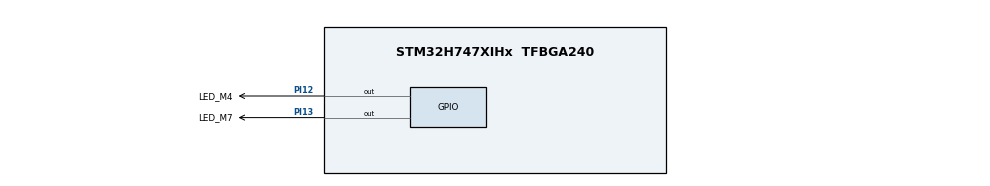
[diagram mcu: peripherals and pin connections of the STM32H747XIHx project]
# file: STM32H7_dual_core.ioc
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CORTEX_M7.CPU_DCache=Enabled
CORTEX_M7.CPU_ICache=Enabled
CortexM4.IPs=BDMA,CORTEX_M4\:I,DEBUG,DMA,FATFS_M4\:I,FREERTOS_M4\:I,IWDG2\:I,MDMA,NVIC2\:I,OPENAMP_M4\:I,PDM2PCM_M4\:I,PWR,RCC,RESMGR_UTILITY,SYS_M4\:I,USB_DEVICE_M4\:I,USB_HOST_M4\:I,VREFBUF,WWDG2\:I,TIM3\:I
CortexM4.Pins=PI12
CortexM7.IPs=BDMA\:I,CORTEX_M7\:I,DEBUG\:I,DMA\:I,FATFS_M7\:I,FREERTOS_M7\:I,IWDG1\:I,MDMA\:I,NVIC1\:I,OPENAMP_M7\:I,PDM2PCM_M7\:I,PWR\:I,RCC\:I,RESMGR_UTILITY\:I,SYS\:I,USB_DEVICE_M7\:I,USB_HOST_M7\:I,VREFBUF\:I,WWDG1\:I,TIM2\:I
CortexM7.Pins=PI13
FREERTOS_M4.Tasks01=defaultTask,24,256,StartDefaultTask,Default,NULL,Dynamic,NULL,NULL
FREERTOS_M4.configENABLE_FPU=1
FREERTOS_M4.configMINIMAL_STACK_SIZE=256
FREERTOS_M4.configUSE_NEWLIB_REENTRANT=1
FREERTOS_M7.Tasks01=defaultTask,24,128,StartDefaultTask,Default,NULL,Dynamic,NULL,NULL
FREERTOS_M7.configENABLE_FPU=1
FREERTOS_M7.configUSE_NEWLIB_REENTRANT=1
Mcu.Family=STM32H7
Mcu.Name=STM32H747XIHx
Mcu.Package=TFBGA240
NVIC1.PriorityGroup=NVIC_PRIORITYGROUP_4
NVIC1.TIM2_IRQn=true\:15\:0\:false\:false\:true\:false\:false\:true
NVIC1.TimeBase=TIM2_IRQn
NVIC1.TimeBaseIP=TIM2
NVIC2.PriorityGroup=NVIC_PRIORITYGROUP_4
NVIC2.TIM3_IRQn=true\:15\:0\:false\:false\:true\:false\:false\:true
NVIC2.TimeBase=TIM3_IRQn
NVIC2.TimeBaseIP=TIM3
PH0-OSC_IN\ (PH0).Mode=HSE-External-Oscillator
PH0-OSC_IN\ (PH0).PinAttribute=CortexM7
PH0-OSC_IN\ (PH0).Signal=RCC_OSC_IN
PH1-OSC_OUT\ (PH1).Mode=HSE-External-Oscillator
PH1-OSC_OUT\ (PH1).PinAttribute=CortexM7
PH1-OSC_OUT\ (PH1).Signal=RCC_OSC_OUT
PI12.GPIO_Label=LED_M4
PI12.PinAttribute=CortexM4
PI12.Signal=GPIO_Output
PI13.GPIO_Label=LED_M7
PI13.PinAttribute=CortexM7
PI13.Signal=GPIO_Output
ProjectManager.HeapSize=M4-0x200,M7-0x200
ProjectManager.StackSize=M4-0x400,M7-0x400
ProjectManager.TargetToolchain=STM32CubeIDE
RCC.ADCFreq_Value=50390625
RCC.APB1Freq_Value=120000000
RCC.APB2Freq_Value=120000000
RCC.APB3Freq_Value=120000000
RCC.APB4Freq_Value=120000000
RCC.CortexFreq_Value=480000000
RCC.D1PPRE=RCC_APB3_DIV2
RCC.D2PPRE1=RCC_APB1_DIV2
RCC.D2PPRE2=RCC_APB2_DIV2
RCC.D3PPRE=RCC_APB4_DIV2
RCC.DIVM1=5
RCC.DIVN1=192
RCC.HCLKFreq_Value=240000000
RCC.HPRE=RCC_HCLK_DIV2
RCC.PLLFRACN=0
RCC.PLLSourceVirtual=RCC_PLLSOURCE_HSE
RCC.SYSCLKFreq_VALUE=480000000
RCC.SYSCLKSource=RCC_SYSCLKSOURCE_PLLCLK
RCC.USBFreq_Value=480000000
SYS.userName=SYS_M7
VP_FREERTOS_M4_VS_CMSIS_V2.Mode=CMSIS_V2
VP_FREERTOS_M7_VS_CMSIS_V2.Mode=CMSIS_V2
VP_SYS_M4_VS_tim3.Mode=TIM3
VP_SYS_VS_tim2.Mode=TIM2
board=custom

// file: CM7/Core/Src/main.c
/* USER CODE BEGIN Header */
/**
  ******************************************************************************
  * @file           : main.c
  * @brief          : Main program body
  ******************************************************************************
  * @attention
  *
  * <h2><center>&copy; Copyright (c) 2021 STMicroelectronics.
  * All rights reserved.</center></h2>
  *
  * This software component is licensed by ST under BSD 3-Clause license,
  * the "License"; You may not use this file except in compliance with the
  * License. You may obtain a copy of the License at:
  *                        opensource.org/licenses/BSD-3-Clause
  *
  ******************************************************************************
  */
/* USER CODE END Header */
#include "main.h"
#include "cmsis_os.h"

/* USER CODE BEGIN Includes */
#include "cm_ipc.h"
#include <stdio.h>
#include "stm32h747i_discovery.h"
#include "hal_stm_lvgl/tft/tft.h"
#include "hal_stm_lvgl/touchpad/touchpad.h"
#include "lvgl/lvgl.h"
#include "GUI/gui.h"
/* USER CODE END Includes */

/* USER CODE BEGIN PTD */
volatile int lv_started = 0;
void GUITask(void *argument);
osThreadId_t guiTaskHandle;
const osThreadAttr_t guiTask_attributes = {
  .name = "GUITask",
  .stack_size = 1024 * 3,
  .priority = (osPriority_t) osPriorityLow,
};

void MPU_Config( void )
{
  MPU_Region_InitTypeDef MPU_InitStruct;

  /* Disable the MPU */
  HAL_MPU_Disable();

  /* Setup AXI SRAM in Write-through */
  MPU_InitStruct.Enable           = MPU_REGION_ENABLE;
  MPU_InitStruct.BaseAddress      = D1_AXISRAM_BASE;
  MPU_InitStruct.Size             = MPU_REGION_SIZE_512KB;
  MPU_InitStruct.AccessPermission = MPU_REGION_FULL_ACCESS;
  MPU_InitStruct.IsBufferable     = MPU_ACCESS_NOT_BUFFERABLE;
  MPU_InitStruct.IsCacheable      = MPU_ACCESS_CACHEABLE;
  MPU_InitStruct.IsShareable      = MPU_ACCESS_NOT_SHAREABLE;
  MPU_InitStruct.Number           = MPU_REGION_NUMBER0;
  MPU_InitStruct.TypeExtField     = MPU_TEX_LEVEL0;
  MPU_InitStruct.SubRegionDisable = 0x00;
  MPU_InitStruct.DisableExec      = MPU_INSTRUCTION_ACCESS_DISABLE;
  HAL_MPU_ConfigRegion(&MPU_InitStruct);

  /* Disable access to D2 SRAM1 */
  MPU_InitStruct.Enable           = MPU_REGION_ENABLE;
  MPU_InitStruct.BaseAddress      = D2_AXISRAM_BASE;
  MPU_InitStruct.Size             = MPU_REGION_SIZE_256KB;
  MPU_InitStruct.AccessPermission = MPU_REGION_NO_ACCESS;
  MPU_InitStruct.IsBufferable     = MPU_ACCESS_NOT_BUFFERABLE;
  MPU_InitStruct.IsCacheable      = MPU_ACCESS_NOT_CACHEABLE;
  MPU_InitStruct.IsShareable      = MPU_ACCESS_NOT_SHAREABLE;
  MPU_InitStruct.Number           = MPU_REGION_NUMBER1;
  MPU_InitStruct.TypeExtField     = MPU_TEX_LEVEL0;
  MPU_InitStruct.SubRegionDisable = 0x00;
  MPU_InitStruct.DisableExec      = MPU_INSTRUCTION_ACCESS_DISABLE;
  HAL_MPU_ConfigRegion(&MPU_InitStruct);

  /* Setup D2 SRAM2 as device memory */
  MPU_InitStruct.Enable           = MPU_REGION_ENABLE;
  MPU_InitStruct.BaseAddress      = (D2_AXISRAM_BASE + 0x40000);
  MPU_InitStruct.Size             = MPU_REGION_SIZE_32KB;
  MPU_InitStruct.AccessPermission = MPU_REGION_FULL_ACCESS;
  MPU_InitStruct.IsBufferable     = MPU_ACCESS_BUFFERABLE;
  MPU_InitStruct.IsCacheable      = MPU_ACCESS_NOT_CACHEABLE;
  MPU_InitStruct.IsShareable      = MPU_ACCESS_NOT_SHAREABLE;
  MPU_InitStruct.Number           = MPU_REGION_NUMBER2;
  MPU_InitStruct.TypeExtField     = MPU_TEX_LEVEL0;
  MPU_InitStruct.SubRegionDisable = 0x00;
  MPU_InitStruct.DisableExec      = MPU_INSTRUCTION_ACCESS_DISABLE;
  HAL_MPU_ConfigRegion(&MPU_InitStruct);

	// Enable D-cache on SDRAM (Write-through)
  MPU_InitStruct.Enable           = MPU_REGION_ENABLE;
  MPU_InitStruct.BaseAddress      = 0xD0000000U;
  MPU_InitStruct.Size             = MPU_REGION_SIZE_32MB;
  MPU_InitStruct.AccessPermission = MPU_REGION_FULL_ACCESS;
  MPU_InitStruct.IsBufferable     = MPU_ACCESS_NOT_BUFFERABLE;
  MPU_InitStruct.IsCacheable      = MPU_ACCESS_CACHEABLE;
  MPU_InitStruct.IsShareable      = MPU_ACCESS_NOT_SHAREABLE;
  MPU_InitStruct.Number           = MPU_REGION_NUMBER3;
  MPU_InitStruct.TypeExtField     = MPU_TEX_LEVEL0;
  MPU_InitStruct.SubRegionDisable = 0x00;
  MPU_InitStruct.DisableExec      = MPU_INSTRUCTION_ACCESS_DISABLE;
  HAL_MPU_ConfigRegion(&MPU_InitStruct);

  /* Disable access to D2 SRAM3 */
  /*
  MPU_InitStruct.Enable           = MPU_REGION_ENABLE;
  MPU_InitStruct.BaseAddress      = D3_SRAM_BASE;
  MPU_InitStruct.Size             = MPU_REGION_SIZE_64KB;
  MPU_InitStruct.AccessPermission = MPU_REGION_NO_ACCESS;
  MPU_InitStruct.IsBufferable     = MPU_ACCESS_BUFFERABLE;
  MPU_InitStruct.IsCacheable      = MPU_ACCESS_NOT_CACHEABLE;
  MPU_InitStruct.IsShareable      = MPU_ACCESS_NOT_SHAREABLE;
  MPU_InitStruct.Number           = MPU_REGION_NUMBER7;
  MPU_InitStruct.TypeExtField     = MPU_TEX_LEVEL0;
  MPU_InitStruct.SubRegionDisable = 0x00;
  MPU_InitStruct.DisableExec      = MPU_INSTRUCTION_ACCESS_DISABLE;
  HAL_MPU_ConfigRegion(&MPU_InitStruct);
  */

  HAL_MPU_Enable(MPU_PRIVILEGED_DEFAULT);
}
/* USER CODE END PTD */

/* USER CODE BEGIN PD */

#ifndef HSEM_ID_0
#define HSEM_ID_0 (0U) /* HW semaphore 0*/
#endif
/* USER CODE END PD */

/* Definitions for defaultTask */
osThreadId_t defaultTaskHandle;
const osThreadAttr_t defaultTask_attributes = {
  .name = "defaultTask",
  .stack_size = 128 * 4,
  .priority = (osPriority_t) osPriorityNormal,
};
/* USER CODE BEGIN PV */
#if configAPPLICATION_ALLOCATED_HEAP == 1
#if defined ( __ICCARM__ )
#pragma location="heap_mem"
#else
__attribute__((section("heap_mem")))
#endif
uint8_t ucHeap[ configTOTAL_HEAP_SIZE ];
#endif /* configAPPLICATION_ALLOCATED_HEAP */

uint8_t                 DualCoreEnabled = 0;

/* USER CODE END PV */

void SystemClock_Config(void);
static void MX_GPIO_Init(void);
void StartDefaultTask(void *argument);

int main(void)
{
  /* USER CODE BEGIN 1 */
  /* Wait until CPU2 boots and enters in stop mode or timeout*/
  int32_t timeout = 0xFFFF;
  while((__HAL_RCC_GET_FLAG(RCC_FLAG_D2CKRDY) != RESET) && (timeout-- > 0));
  if ( timeout == 0 )
  {
	DualCoreEnabled = 0;
  }
  else
  {
	DualCoreEnabled = 1;
  }

  MPU_Config();
  /* USER CODE END 1 */
/* USER CODE BEGIN Boot_Mode_Sequence_0 */
  //int32_t timeout;
/* USER CODE END Boot_Mode_Sequence_0 */

  /* Enable I-Cache---------------------------------------------------------*/
  SCB_EnableICache();

  /* Enable D-Cache---------------------------------------------------------*/
  SCB_EnableDCache();

/* USER CODE BEGIN Boot_Mode_Sequence_1 */
  /* Wait until CPU2 boots and enters in stop mode or timeout*/
  //timeout = 0xFFFF;
  /*
  while((__HAL_RCC_GET_FLAG(RCC_FLAG_D2CKRDY) != RESET) && (timeout-- > 0));
  if ( timeout < 0 )
  {
  Error_Handler();
  }
  */
/* USER CODE END Boot_Mode_Sequence_1 */
  /* MCU Configuration--------------------------------------------------------*/

  /* Reset of all peripherals, Initializes the Flash interface and the Systick. */
  HAL_Init();

  /* USER CODE BEGIN Init */
  /* WA : Allow Debugger to connect under reset */
  //HAL_Delay(1000);
  /* USER CODE END Init */

  /* Configure the system clock */
  SystemClock_Config();
/* USER CODE BEGIN Boot_Mode_Sequence_2 */
/* When system initialization is finished, Cortex-M7 will release Cortex-M4 by means of
HSEM notification */
#if 0
/*HW semaphore Clock enable*/
__HAL_RCC_HSEM_CLK_ENABLE();
/*Take HSEM */
HAL_HSEM_FastTake(HSEM_ID_0);
/*Release HSEM in order to notify the CPU2(CM4)*/
HAL_HSEM_Release(HSEM_ID_0,0);
/* wait until CPU2 wakes up from stop mode */
timeout = 0xFFFF;
while((__HAL_RCC_GET_FLAG(RCC_FLAG_D2CKRDY) == RESET) && (timeout-- > 0));
if ( timeout < 0 )
{
Error_Handler();
}
#endif
	if(DualCoreEnabled)
	{
	  /* Initialize FreeRTOS/AMP IPC */
	  ipc_init();

	  //printf("Resuming CPU2 : ");
	  /*HW semaphore Clock enable*/
	  __HAL_RCC_HSEM_CLK_ENABLE();
	  /*Take HSEM */
	  HAL_HSEM_FastTake(HSEM_ID_0);
	  /*Release HSEM in order to notify the CPU2(CM4)*/
	  HAL_HSEM_Release(HSEM_ID_0, 0);
	  /* Wait until CPU2 boots and enters in stop mode or timeout*/
	  timeout = 0xFFFF;
	  while((__HAL_RCC_GET_FLAG(RCC_FLAG_D2CKRDY) == RESET) && (timeout-- > 0));
	  //if ( timeout == 0 )
		//printf("KO\n");
	  //else
		//printf("OK\n");
	}
/* USER CODE END Boot_Mode_Sequence_2 */

  /* Initialize all configured peripherals */
  MX_GPIO_Init();

  /* Init scheduler */
  osKernelInitialize();

  /* Create the thread(s) */
  /* creation of defaultTask */
  defaultTaskHandle = osThreadNew(StartDefaultTask, NULL, &defaultTask_attributes);

  /* creation of GUITask */
  guiTaskHandle = osThreadNew(GUITask, NULL, &guiTask_attributes);

  /* Start scheduler */
  osKernelStart();

  /* We should never get here as control is now taken by the scheduler */
  /* Infinite loop */
  while (1)
  {

  }
}

void SystemClock_Config(void)
{
  RCC_OscInitTypeDef RCC_OscInitStruct = {0};
  RCC_ClkInitTypeDef RCC_ClkInitStruct = {0};

  /** Supply configuration update enable
  */
  HAL_PWREx_ConfigSupply(PWR_DIRECT_SMPS_SUPPLY);
  /** Configure the main internal regulator output voltage
  */
  __HAL_PWR_VOLTAGESCALING_CONFIG(PWR_REGULATOR_VOLTAGE_SCALE0);

  while(!__HAL_PWR_GET_FLAG(PWR_FLAG_VOSRDY)) {}
  /** Initializes the RCC Oscillators according to the specified parameters
  * in the RCC_OscInitTypeDef structure.
  */
  RCC_OscInitStruct.OscillatorType = RCC_OSCILLATORTYPE_HSE;
  RCC_OscInitStruct.HSEState = RCC_HSE_ON;
  RCC_OscInitStruct.PLL.PLLState = RCC_PLL_ON;
  RCC_OscInitStruct.PLL.PLLSource = RCC_PLLSOURCE_HSE;
  RCC_OscInitStruct.PLL.PLLM = 5;
  RCC_OscInitStruct.PLL.PLLN = 192;
  RCC_OscInitStruct.PLL.PLLP = 2;
  RCC_OscInitStruct.PLL.PLLQ = 2;
  RCC_OscInitStruct.PLL.PLLR = 2;
  RCC_OscInitStruct.PLL.PLLRGE = RCC_PLL1VCIRANGE_2;
  RCC_OscInitStruct.PLL.PLLVCOSEL = RCC_PLL1VCOWIDE;
  RCC_OscInitStruct.PLL.PLLFRACN = 0;
  if (HAL_RCC_OscConfig(&RCC_OscInitStruct) != HAL_OK)
  {
    Error_Handler();
  }
  /** Initializes the CPU, AHB and APB buses clocks
  */
  RCC_ClkInitStruct.ClockType = RCC_CLOCKTYPE_HCLK|RCC_CLOCKTYPE_SYSCLK
                              |RCC_CLOCKTYPE_PCLK1|RCC_CLOCKTYPE_PCLK2
                              |RCC_CLOCKTYPE_D3PCLK1|RCC_CLOCKTYPE_D1PCLK1;
  RCC_ClkInitStruct.SYSCLKSource = RCC_SYSCLKSOURCE_PLLCLK;
  RCC_ClkInitStruct.SYSCLKDivider = RCC_SYSCLK_DIV1;
  RCC_ClkInitStruct.AHBCLKDivider = RCC_HCLK_DIV2;
  RCC_ClkInitStruct.APB3CLKDivider = RCC_APB3_DIV2;
  RCC_ClkInitStruct.APB1CLKDivider = RCC_APB1_DIV2;
  RCC_ClkInitStruct.APB2CLKDivider = RCC_APB2_DIV2;
  RCC_ClkInitStruct.APB4CLKDivider = RCC_APB4_DIV2;

  if (HAL_RCC_ClockConfig(&RCC_ClkInitStruct, FLASH_LATENCY_4) != HAL_OK)
  {
    Error_Handler();
  }
}

static void MX_GPIO_Init(void)
{
  GPIO_InitTypeDef GPIO_InitStruct = {0};

  /* GPIO Ports Clock Enable */
  __HAL_RCC_GPIOI_CLK_ENABLE();
  __HAL_RCC_GPIOH_CLK_ENABLE();

  /*Configure GPIO pin Output Level */
  HAL_GPIO_WritePin(LED_M7_GPIO_Port, LED_M7_Pin, GPIO_PIN_RESET);

  /*Configure GPIO pin : LED_M7_Pin */
  GPIO_InitStruct.Pin = LED_M7_Pin;
  GPIO_InitStruct.Mode = GPIO_MODE_OUTPUT_PP;
  GPIO_InitStruct.Pull = GPIO_NOPULL;
  GPIO_InitStruct.Speed = GPIO_SPEED_FREQ_LOW;
  HAL_GPIO_Init(LED_M7_GPIO_Port, &GPIO_InitStruct);
}

/* USER CODE BEGIN 4 */

void GUITask(void *argument)
{
  /* USER CODE BEGIN 5 */
	tft_init_1();
	lv_init();
	tft_init_2();
	touchpad_init();

	lv_started = 1;

	lv_init_widgets();

	while(1) {
		if (xSemaphoreTake(GUI_mutex, portMAX_DELAY) == pdTRUE){
			lv_task_handler();
			xSemaphoreGive(GUI_mutex);
		}
		vTaskDelay(5);
	}
  /* USER CODE END 5 */
}

static void send_message(uint32_t cnt)
{
    struct ipc_msg msg;
    size_t len;

    /* Render a 160x120 julia fractal on the CM4 core */
    msg.m.command = 1;	// Blink LED
    msg.arg1 = cnt;		// how many blinks
    //msg.arg2 = 3;
    //msg.arg3 = 4;

    len = ipc_sendmsg(&msg, sizeof(msg));
    configASSERT(len == sizeof(msg));
}

static int wait_completion(uint32_t timeout)
{
    struct ipc_msg msg = { 0, };
    size_t len;
    uint32_t StartTime = xTaskGetTickCount();

    do {
        len = ipc_recvmsg(&msg, sizeof(msg), timeout);
        if(len != sizeof(msg))
            return 1;
        if(xTaskGetTickCount() > (StartTime + timeout))
            return 2;
    } while (msg.arg1 != 256);

    return 0;
}

/* USER CODE END 4 */

void StartDefaultTask(void *argument)
{
  /* USER CODE BEGIN 5 */
	static uint32_t cnt = 3;
	do{
		vTaskDelay(10);
	}while(is_ipc_started() == 0);
  /* Infinite loop */
  for(;;)
  {
	  /*Configure GPIO pin Output Level */
	  HAL_GPIO_TogglePin(LED_M7_GPIO_Port, LED_M7_Pin);
	  vTaskDelay(250);
	  HAL_GPIO_TogglePin(LED_M7_GPIO_Port, LED_M7_Pin);
	  vTaskDelay(250);
	  send_message(cnt);
	  int ret = wait_completion((cnt * 1000) + 100);
	  cnt++;
	  if (cnt >= 8){
		  cnt = 3;
	  }

	  // Blink two times if worked, three times if not
	  int i = 0;
	  if (!ret){
		  for(i=0;i<4;i++){
			  HAL_GPIO_TogglePin(LED_M7_GPIO_Port, LED_M7_Pin);
			  vTaskDelay(250);
		  }
	  }else{
		  for(i=0;i<8;i++){
			  HAL_GPIO_TogglePin(LED_M7_GPIO_Port, LED_M7_Pin);
			  vTaskDelay(250);
		  }
	  }
  }
  /* USER CODE END 5 */
}

void HAL_TIM_PeriodElapsedCallback(TIM_HandleTypeDef *htim)
{
  if (htim->Instance == TIM2) {
    HAL_IncTick();
  }
  /* USER CODE BEGIN Callback 1 */
  if (lv_started){
	  lv_tick_inc(1);
  }
  /* USER CODE END Callback 1 */
}

void Error_Handler(void)
{
  __disable_irq();
  while (1)
  {
  }
}

/************************ (C) COPYRIGHT STMicroelectronics *****END OF FILE****/
